# RA register map
Vendor: Renesas; Series: All Chips; File version: x.xx
Registers are 32-bit, read-write, reset 0x0 unless marked. A register's access mark holds for its fields unless they carry their own. Offsets are from the block's base; [hi:lo] are bit positions; lines under a group give offsets from that group; {n}, {i} and the like mark numbered series; 'fields as' and 'values as' point back to an identical list.

## R_USB_FS0 — USB 2.0 Module
Base 0x40090000
Same registers: R_USB_HS0 0x40060000
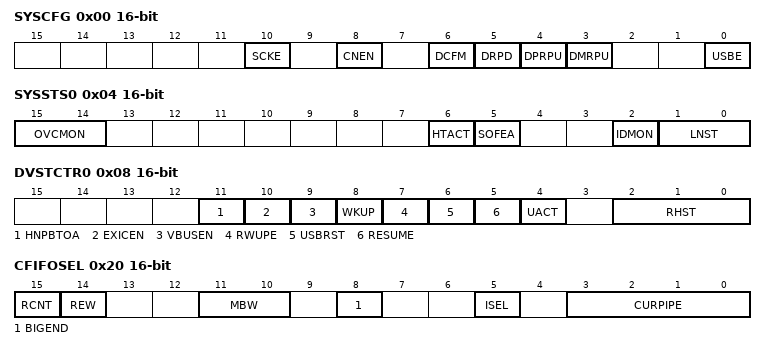
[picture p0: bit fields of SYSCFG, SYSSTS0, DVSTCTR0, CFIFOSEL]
0x00 SYSCFG 16-bit — System Configuration Control Register
  [10] SCKE — USB Clock Enable
    0=Clock supply to the USBFS stopped; 1=Clock supply to the USBFS enabled
  [8] CNEN — CNEN Single End Receiver Enable
    0=Single end receiver disabled; 1=Single end receiver enabled
  [6] DCFM — Controller Function Select
    0=Device controller selected; 1=Host controller selected
  [5] DRPD — D+/D- Line Resistor Control
    0=Line pull-down disabled; 1=Line pull-down enabled
  [4] DPRPU — D+ Line Resistor Control
    0=Line pull-down disabled; 1=Line pull-down enabled
  [3] DMRPU — D- Line Resistor Control
    0=Line pull-up disabled; 1=Line pull-up enabled
  [0] USBE — USB Operation Enable
    0=Disabled; 1=Enabled
0x02 BUSWAIT 16-bit reset 0xF — CPU Bus Wait Register
  [3:0] BWAIT — CPU Bus Access Wait Specification BWAIT waits (BWAIT+2 access cycles)
    other=BWAIT (BWAIT wait(s) ( BWAIT + 2 access cycles ))
0x04 SYSSTS0 16-bit ro reset not defined — System Configuration Status Register 0
  [15:14] OVCMON — External USB0_OVRCURA/ USB0_OVRCURB Input Pin MonitorThe OCVMON[1] bit indicates the status of the USBHS_OVRCURA pin. The OCVMON[0] bit indicates the status of the USBHS_OVRCURB pin.
  [6] HTACT — USB Host Sequencer Status Monitor
    0=Host sequencer completely stopped; 1=Host sequencer not completely stopped
  [5] SOFEA — SOF Active Monitor While Host Controller Function is Selected.
    0=SOF output is stopped; 1=SOF output is operating
  [2] IDMON — External ID0 Input Pin Monitor
    0=USB0_ID pin is low; 1=USB0_ID pin is high
  [1:0] LNST — USB Data Line Status Monitor
    0=SE0; 1=K-State (FS) / J-State(LS); 2=J-State(FS) / K-State(LS); 3=SE1
0x06 PLLSTA 16-bit ro — PLL Status Register
  [0] PLLLOCK — PLL Lock Flag
    0=PLL is not locked; 1=PLL is locked
0x08 DVSTCTR0 16-bit — Device State Control Register 0
  [11] HNPBTOA — Host Negotiation Protocol (HNP) Control This bit is used when switching from device B to device A while in OTG mode. If the HNPBTOA bit is 1, the internal function control keeps the suspended state until the HNP processing ends even though SYSCFG.DPRPU = 0 or SYSCFG.DCFM = 1 is set.
    0=Normal Operation; 1=Switching from device B to device A is enabled
  [10] EXICEN — USB_EXICEN Output Pin Control
    0=External USB_EXICEN pin outputs low; 1=External USB_EXICEN pin outputs high
  [9] VBUSEN — USB_VBUSEN Output Pin Control
    0=External USB_VBUSEN pin outputs low; 1=External USB_VBUSEN pin outputs high
  [8] WKUP — Wakeup Output
    0=Remote wakeup signal is not output; 1=Remote wakeup signal is output
  [7] RWUPE — Wakeup Detection Enable
    0=Downstream port wakeup is disabled; 1=Downstream port wakeup is enabled
  [6] USBRST — USB Bus Reset Output
    0=USB bus reset signal is not output; 1=USB bus reset signal is output
  [5] RESUME — Resume Output
    0=Resume signal is not output; 1=Resume signal is output
  [4] UACT — USB Bus Enable
    0=Downstream port is disabled (SOF transmission is disabled); 1=Downstream port is enabled (SOF transmission is enabled)
  [2:0] RHST ro — USB Bus Reset Status
    0=Communication speed not determined; 1=Low-speed connection(When the host controller is selected) /USB bus reset in progress( When the function controller is selected); 2=Full-speed connection(When the host controller is selected) /USB bus reset in progress or full-speed connection(When the function controller is selected); 3=Setting prohibited; other=others (USB bus reset in progress(When the host controller function is selected))
0x0C TESTMODE 16-bit — USB Test Mode Register
  [3:0] UTST — Test Mode
    0=Normal operation; 1=Test_J TestMode(When the Function Controller Function is Selected); 2=Test_K TestMode(When the Function Controller Function is Selected); 3=Test_SE0_NAK TestMode(When the Function Controller Function is Selected); 4=Test_Packet TestMode(When the Function Controller Function is Selected); 5=Reserved TestMode(When the Function Controller Function is Selected); 6=Reserved TestMode(When the Function Controller Function is Selected); 7=Reserved TestMode(When the Function Controller Function is Selected); 9=Test_J TestMode(When the Host Controller Function is Selected); 10=Test_K TestMode(When the Host Controller Function is Selected); 11=Test_SE0_NAK TestMode(When the Host Controller Function is Selected); 12=Test_Packet TestMode(When the Host Controller Function is Selected); 13=Test_Force_EnableTestMode(When the Host Controller Function is Selected); 14=Reserved TestMode(When the Host Controller Function is Selected); 15=Reserved TestMode(When the Host Controller Function is Selected)
0x14 CFIFOL 16-bit — CFIFO Port Register L
0x14 CFIFOLL 8-bit (alternate view of CFIFOL) — CFIFO Port Register LL
0x14 CFIFO (alternate view of CFIFOL) — CFIFO Port Register
0x16 CFIFOH 16-bit (alternate view of CFIFO) — CFIFO Port Register H
0x17 CFIFOHH 8-bit (alternate view of CFIFOH) — CFIFO Port Register HH
0x18 D0FIFOL 16-bit — D0FIFO Port Register L
0x18 D0FIFOLL 8-bit (alternate view of D0FIFOL) — D0FIFO Port Register LL
0x18 D0FIFO (alternate view of D0FIFOL) — D0FIFO Port Register
0x1A D0FIFOH 16-bit (alternate view of D0FIFO) — D0FIFO Port Register H
0x1B D0FIFOHH 8-bit (alternate view of D0FIFOH) — D0FIFO Port Register HH
0x1C D1FIFOL 16-bit — D1FIFO Port Register L
0x1C D1FIFOLL 8-bit (alternate view of D1FIFOL) — D1FIFO Port Register LL
0x1C D1FIFO (alternate view of D1FIFOL) — D1FIFO Port Register
0x1E D1FIFOH 16-bit (alternate view of D1FIFO) — D1FIFO Port Register H
0x1F D1FIFOHH 8-bit (alternate view of D1FIFOH) — D1FIFO Port Register HH
0x20 CFIFOSEL 16-bit — CFIFO Port Select Register
  [15] RCNT — Read Count Mode
    0=The DTLN[8:0] bits (CFIFOCRT.DTLN[8:0], D0FIFOCRT.DTLN[8:0], D1FIFOCRT.DTLN[8:0]) are cleared when all of the receive data has been read from the CFIFO.(In double buffer mode, the DTLN[8:0] bit value is cleared when all the data has been read from only a single plane.); 1=The DTLN[8:0] bits are decremented each time the receive data is read from the CFIFO
  [14] REW — Buffer Pointer Rewind
    0=The buffer pointer is not rewound; 1=The buffer pointer is rewound
  [11:10] MBW — CFIFO Port Access Bit Width
    0=8-bit width; 1=16-bit width; 2=32-bit width
  [8] BIGEND — CFIFO Port Endian Control
    0=Little endian; 1=Big endian
  [5] ISEL — CFIFO Port Access Direction When DCP is Selected
    0=Reading from the buffer memory is selected; 1=Writing to the buffer memory is selected
  [3:0] CURPIPE — CFIFO Port Access Pipe Specification
    0=DCP (Default control pipe); {v}=Pipe {v} (v=1..9); other=others (Setting prohibited)
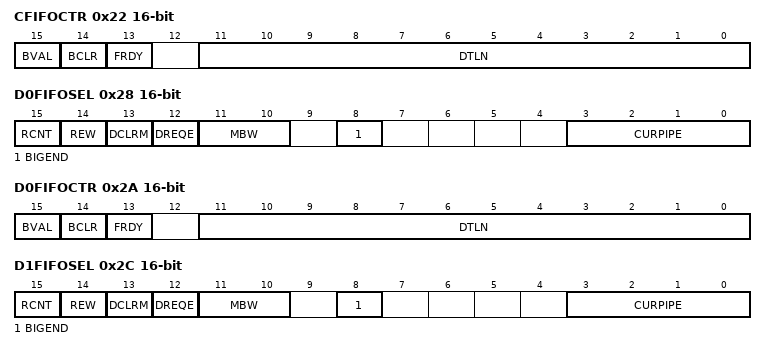
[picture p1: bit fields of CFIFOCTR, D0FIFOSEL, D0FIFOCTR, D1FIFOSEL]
0x22 CFIFOCTR 16-bit — CFIFO Port Control Register
  [15] BVAL — Buffer Memory Valid Flag
    0=Invalid; 1=Writing ended
  [14] BCLR — CPU Buffer ClearNote: Only 0 can be read.
    0=Does not operate; 1=FIFO buffer cleared on the CPU side
  [13] FRDY ro — FIFO Port Ready
    0=FIFO port access is disabled; 1=FIFO port access is enabled
  [11:0] DTLN ro — Receive Data LengthIndicates the length of the receive data.
0x28 D0FIFOSEL 16-bit — D0FIFO Port Select Register
  [15] RCNT — Read Count Mode
    0=The DTLN[8:0] bits (CFIFOCRT.DTLN[8:0], D0FIFOCRT.DTLN[8:0], D1FIFOCRT.DTLN[8:0]) are cleared when all of the receive data has been read from the DnFIFO.(In double buffer mode, the DTLN bit Value is cleared when all the data has been read from only a single plane.); 1=The DTLN[8:0] bits are decremented each time the receive data is read from the DnFIFO. (n = 0, 1)
  [14] REW — Buffer Pointer RewindNote: Only 0 can be read.
    values as CFIFOSEL.REW
  [13] DCLRM — Auto Buffer Memory Clear Mode Accessed after Specified Pipe Data is Read
    0=Auto buffer clear mode is disabled; 1=Auto buffer clear mode is enabled
  [12] DREQE — DMA/DTC Transfer Request Enable
    0=DMA/DTC transfer request is disabled; 1=DMA/DTC transfer request is enabled
  [11:10] MBW — FIFO Port Access Bit Width
    0=8-bit width; 1=16-bit width; 2=32-bit width
  [8] BIGEND — FIFO Port Endian Control
    0=Little endian; 1=Big endian
  [3:0] CURPIPE — FIFO Port Access Pipe Specification
    values as CFIFOSEL.CURPIPE
0x2A D0FIFOCTR 16-bit — D0FIFO Port Control Register
  fields as CFIFOCTR
0x2C D1FIFOSEL 16-bit — D1FIFO Port Select Register
  [15] RCNT — Read Count Mode
    values as D0FIFOSEL.RCNT
  [14] REW — Buffer Pointer Rewind
    values as CFIFOSEL.REW
  [13] DCLRM — Auto Buffer Memory Clear Mode Accessed after Specified Pipe Data is Read
    values as D0FIFOSEL.DCLRM
  [12] DREQE — DMA/DTC Transfer Request Enable
    values as D0FIFOSEL.DREQE
  [11:10] MBW — FIFO Port Access Bit Width
    0=8-bit width; 1=16-bit width; 2=32-bit width
  [8] BIGEND — FIFO Port Endian Control
    0=Little endian; 1=Big endian
  [3:0] CURPIPE — FIFO Port Access Pipe Specification
    values as CFIFOSEL.CURPIPE
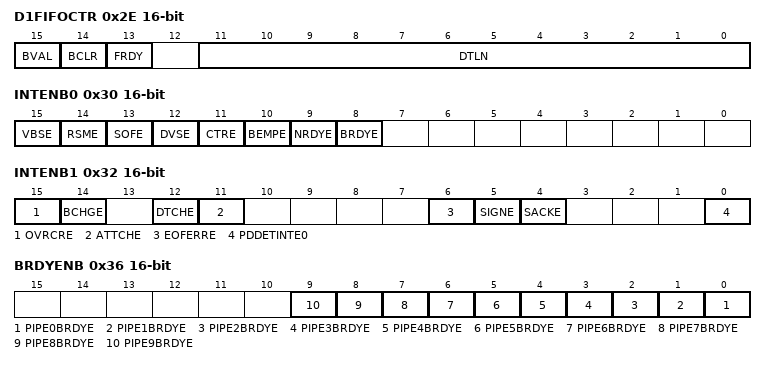
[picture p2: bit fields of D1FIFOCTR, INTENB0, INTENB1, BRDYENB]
0x2E D1FIFOCTR 16-bit — D1FIFO Port Control Register
  fields as CFIFOCTR
0x30 INTENB0 16-bit — Interrupt Enable Register 0
  [all] fields
    0=Interrupt output disabled; 1=Interrupt output enabled
  [15] VBSE — VBUS Interrupt Enable
  [14] RSME — Resume Interrupt Enable
  [13] SOFE — Frame Number Update Interrupt Enable
  [12] DVSE — Device State Transition Interrupt Enable
  [11] CTRE — Control Transfer Stage Transition Interrupt Enable
  [10] BEMPE — Buffer Empty Interrupt Enable
  [9] NRDYE — Buffer Not Ready Response Interrupt Enable
  [8] BRDYE — Buffer Ready Interrupt Enable
0x32 INTENB1 16-bit — Interrupt Enable Register 1
  [all] fields
    0=Interrupt output disabled; 1=Interrupt output enabled
  [15] OVRCRE — Overcurrent Input Change Interrupt Enable
  [14] BCHGE — USB Bus Change Interrupt Enable
  [12] DTCHE — Disconnection Detection Interrupt Enable
  [11] ATTCHE — Connection Detection Interrupt Enable
  [6] EOFERRE — EOF Error Detection Interrupt Enable
  [5] SIGNE — Setup Transaction Error Interrupt Enable
  [4] SACKE — Setup Transaction Normal Response Interrupt Enable
  [0] PDDETINTE0 — PDDETINT0 Detection Interrupt Enable
0x36 BRDYENB 16-bit — BRDY Interrupt Enable Register
  [n] PIPE{n}BRDYE (n=0..9) — BRDY Interrupt Enable for PIPE
    0=Interrupt output disabled; 1=Interrupt output enabled
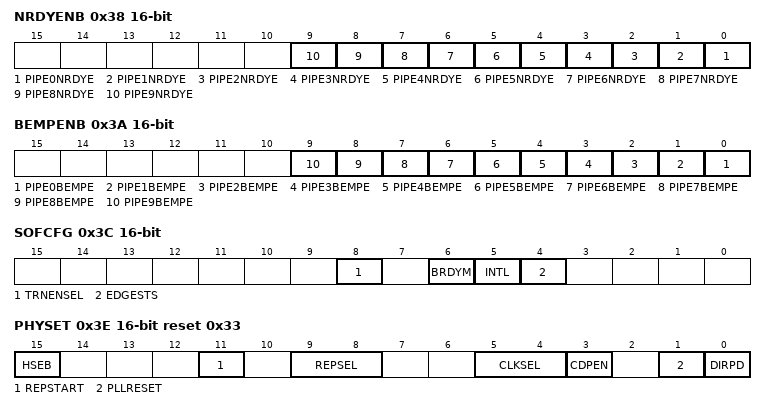
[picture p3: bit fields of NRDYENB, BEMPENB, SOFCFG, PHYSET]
0x38 NRDYENB 16-bit — NRDY Interrupt Enable Register
  [n] PIPE{n}NRDYE (n=0..9) — NRDY Interrupt Enable for PIPE
    0=Interrupt output disabled; 1=Interrupt output enabled
0x3A BEMPENB 16-bit — BEMP Interrupt Enable Register
  [n] PIPE{n}BEMPE (n=0..9) — BEMP Interrupt Enable for PIPE
    0=Interrupt output disabled; 1=Interrupt output enabled
0x3C SOFCFG 16-bit — SOF Output Configuration Register
  [8] TRNENSEL — Transaction-Enabled Time Select
    0=Not low-speed communication; 1=Low-speed communication
  [6] BRDYM — BRDY Interrupt Status Clear Timing
    0=BRDY flag cleared by software; 1=BRDY flag cleared by the USBFS through a data read from the FIFO buffer or data write to the FIFO buffer
  [5] INTL — Interrupt Output Sense Select
    0=Edge sense; 1=Level sense
  [4] EDGESTS ro — Edge Interrupt Output Status Monitor
    0=before stopping the clock supply to the USB module; 1=the edge interrupt output signal is in the middle of the edge processing
0x3E PHYSET 16-bit reset 0x33 (reset mask 0xB3B) — PHY Setting Register
  [15] HSEB — CL-Only Mode
    0=CL-only mode is not activated; 1=CL-only mode is activated
  [11] REPSTART — Forcibly Start Terminating Resistance Adjustment
    0=Terminating resistance adjustment is forcibly started; 1=Terminating resistance adjustment is not forcibly started
  [9:8] REPSEL — Terminating Resistance Adjustment Cycle
    0=No cycle is set; 1=Adjust terminating resistance at 16-second intervals; 2=Adjust terminating resistance at 64-second intervals; 3=Adjust terminating resistance at 128-second intervals
  [5:4] CLKSEL — Input System Clock Frequency
    0=Setting Prohibited; 1=12 MHz; 2=20 MHz; 3=24 MHz
  [3] CDPEN — Charging Downstream Port Enable
    0=Disable charging downstream port; 1=Enable charging downstream port
  [1] PLLRESET — PLL Reset Control
    0=Disable PLL reset control for UTMI_PHY; 1=Enable PLL reset control for UTMI_PHY
  [0] DIRPD — Power-Down Control
    0=Does not enter low-power consumption mode; 1=Enter low-power consumption mode
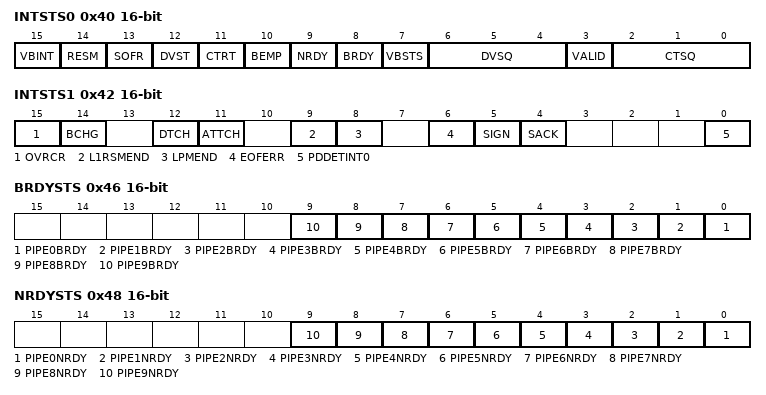
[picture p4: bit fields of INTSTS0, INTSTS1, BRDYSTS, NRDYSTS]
0x40 INTSTS0 16-bit (reset mask 0xFF7F) — Interrupt Status Register 0
  [15] VBINT write-0-clears read-modifies — VBUS Interrupt Status
    0=VBUS interrupts are not generated; 1=VBUS interrupts are generated
  [14] RESM write-0-clears read-modifies — Resume Interrupt Status
    0=Resume interrupts are not generated; 1=Resume interrupts are generated
  [13] SOFR write-0-clears read-modifies — Frame Number Refresh Interrupt Status
    0=SOF interrupts are not generated; 1=SOF interrupts are generated
  [12] DVST write-0-clears read-modifies — Device State Transition Interrupt Status
    0=Device state transition interrupts are not generated; 1=Device state transition interrupts are generated
  [11] CTRT write-0-clears read-modifies — Control Transfer Stage Transition Interrupt Status
    0=Control transfer stage transition interrupts are not generated; 1=Control transfer stage transition interrupts are generated
  [10] BEMP ro — Buffer Empty Interrupt Status
    0=BEMP interrupts are not generated; 1=BEMP interrupts are generated
  [9] NRDY ro — Buffer Not Ready Interrupt Status
    0=NRDY interrupts are not generated; 1=NRDY interrupts are generated
  [8] BRDY ro — Buffer Ready Interrupt Status
    0=BRDY interrupts are not generated; 1=BRDY interrupts are generated
  [7] VBSTS ro — VBUS Input Status
    0=USB_VBUS pin is low; 1=USB_VBUS pin is high
  [6:4] DVSQ ro — Device State
    0=Powered state; 1=Default state; 2=Address state; 3=Configured state; other=others (Suspended state)
  [3] VALID — USB Request Reception
    0=Setup packet is not received; 1=Setup packet is received
  [2:0] CTSQ ro — Control Transfer Stage
    0=Idle or setup stage; 1=Control read data stage; 2=Control read status stage; 3=Control write data stage; 4=Control write status stage; 5=Control write (no data) status stage; 6=Control transfer sequence error; other=others (Setting prohibited)
0x42 INTSTS1 16-bit — Interrupt Status Register 1
  [15] OVRCR write-0-clears read-modifies — Overcurrent Input Change Interrupt Status
    0=OVRCR interrupts are not generated; 1=OVRCR interrupts are generated
  [14] BCHG write-0-clears read-modifies — USB Bus Change Interrupt Status
    0=BCHG interrupts are not generated; 1=BCHG interrupts are generated
  [12] DTCH write-0-clears read-modifies — USB Disconnection Detection Interrupt Status
    0=DTCH interrupts are not generated; 1=DTCH interrupts are generated
  [11] ATTCH write-0-clears read-modifies — ATTCH Interrupt Status
    0=ATTCH interrupts are not generated; 1=ATTCH interrupts are generated
  [9] L1RSMEND write-0-clears read-modifies — L1 Resume End Interrupt Status
    0=L1RSMEND interrupts are not generated; 1=L1RSMEND interrupts are generated
  [8] LPMEND write-0-clears read-modifies — LPM Transaction End Interrupt Status
    0=LPMEND interrupts are not generated; 1=LPMEND interrupts are generated
  [6] EOFERR write-0-clears read-modifies — EOF Error Detection Interrupt Status
    0=EOFERR interrupts are not generated; 1=EOFERR interrupts are generated
  [5] SIGN write-0-clears read-modifies — Setup Transaction Error Interrupt Status
    0=SIGN interrupts are not generated; 1=SIGN interrupts are generated
  [4] SACK write-0-clears read-modifies — Setup Transaction Normal Response Interrupt Status
    0=SACK interrupts are not generated; 1=SACK interrupts are generated
  [0] PDDETINT0 write-0-clears read-modifies — PDDET0 Detection Interrupt Status
    0=PDDET0 detection interrupts are not generated; 1=PDDET0 detection interrupts are generated
0x46 BRDYSTS 16-bit — BRDY Interrupt Status Register
  [n] PIPE{n}BRDY (n=0..9) write-0-clears read-modifies — BRDY Interrupt Status for PIPE
    0=Interrupts are not generated; 1=Interrupts are generated
0x48 NRDYSTS 16-bit — NRDY Interrupt Status Register
  [n] PIPE{n}NRDY (n=0..9) write-0-clears read-modifies — NRDY Interrupt Status for PIPE
    0=Interrupts are not generated; 1=Interrupts are generated
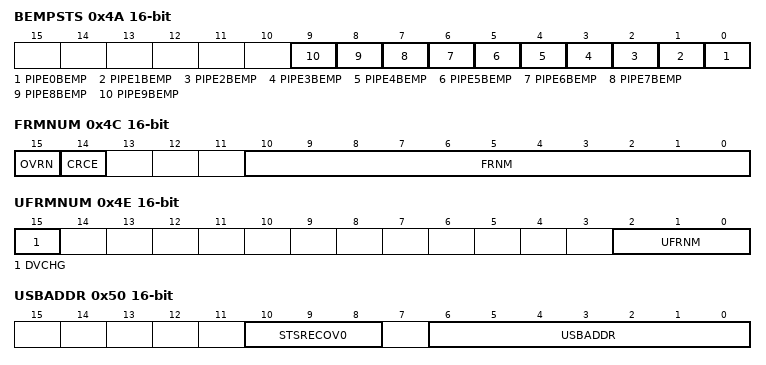
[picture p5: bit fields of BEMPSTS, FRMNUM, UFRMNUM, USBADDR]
0x4A BEMPSTS 16-bit — BEMP Interrupt Status Register
  [n] PIPE{n}BEMP (n=0..9) write-0-clears read-modifies — BEMP Interrupt Status for PIPE
    0=Interrupts are not generated; 1=Interrupts are generated
0x4C FRMNUM 16-bit — Frame Number Register
  [15] OVRN — Overrun/Underrun Detection Status
    0=No error; 1=An error occurred
  [14] CRCE — Receive Data Error
    0=No error; 1=An error occurred
  [10:0] FRNM ro — Frame NumberLatest frame number
0x4E UFRMNUM 16-bit — uFrame Number Register
  [15] DVCHG — Device State Change
    0=Disables the writing to the USBADDR.STSRECOV0[2:0] bits and USBADDR.USBADDR[6:0]; 1=Enables the writing to the USBADDR.STSRECOV0[2:0] bits and USBADDR.USBADDR[6:0]
  [2:0] UFRNM ro — MicroframeIndicate the microframe number.
0x50 USBADDR 16-bit — USB Address Register
  [10:8] STSRECOV0 — Status Recovery
    1=Return to the full-speed state(bits DVSTCTR0.RHST[2:0] = 010b), bits INTSTS0.DVSQ[2:0] = 001b (Default state)(function controller selected); 2=Return to the full-speed state (bits DVSTCTR0.RHST[2:0] = 010b), bits INTSTS0.DVSQ[2:0] = 010b (Address state)(function controller selected)/ Return to the low-speed state (bitsDVSTCTR0.RHST[2:0] = 001b)(host controller is selected); 3=Return to the full-speed state (bits DVSTCTR0.RHST[2:0] = 010b), bits INTSTS0.DVSQ[2:0] = 011b (Configured state)(function controller selected); 4=Return to the full-speed state (bits DVSTCTR0.RHST[2:0] = 010b)(host controller selected); 5=Return to the high-speed state (bits DVSTCTR0.RHST[2:0] = 011b), bits INTSTS0.DVSQ[2:0] = 001b (Default state)(function controller selected); 6=Return to the high-speed state (bits DVSTCTR0.RHST[2:0] = 011b), bits INTSTS0.DVSQ[2:0] = 010b (Address state)(function controller selected)/ Return to the high-speed state (bits DVSTCTR0.RHST[2:0] = 011b)(host controller selected); 7=Return to the high-speed state (bits DVSTCTR0.RHST[2:0] = 011b), bits INTSTS0.DVSQ[2:0] = 011b (Configured state)(function controller selected); other=others (Setting prohibited.)
  [6:0] USBADDR ro — USB Address In device controller mode, these flags indicate the USB address assigned by the host when the USBHS processed the SET_ADDRESS request successfully.
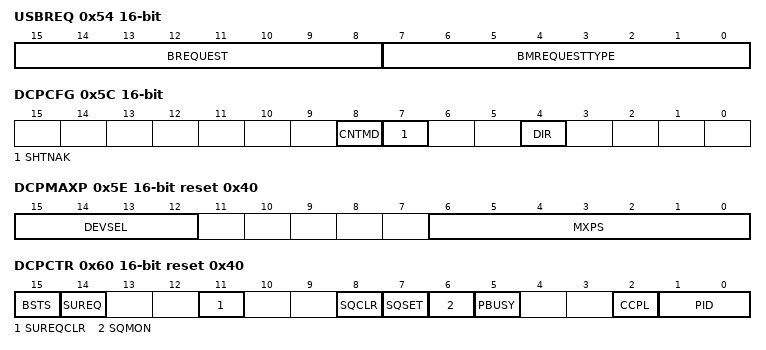
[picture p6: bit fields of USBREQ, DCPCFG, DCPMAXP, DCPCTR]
0x54 USBREQ 16-bit — USB Request Type Register
  [15:8] BREQUEST — RequestThese bits store the USB request bRequest value.
  [7:0] BMREQUESTTYPE — Request TypeThese bits store the USB request bmRequestType value.
0x56 USBVAL 16-bit — USB Request Value Register
  [15:0] WVALUE — ValueThese bits store the USB request Value value.
0x58 USBINDX 16-bit — USB Request Index Register
  [15:0] WINDEX — IndexThese bits store the USB request wIndex value.
0x5A USBLENG 16-bit — USB Request Length Register
  [15:0] WLENGTH — LengthThese bits store the USB request wLength value.
0x5C DCPCFG 16-bit — DCP Configuration Register
  [8] CNTMD — Continuous Transfer Mode
    0=Non-continuous transfer mode; 1=Continuous transfer mode
  [7] SHTNAK — Pipe Disabled at End of Transfer
    0=Pipe continued at the end of transfer; 1=Pipe disabled at the end of transfer
  [4] DIR — Transfer Direction
    0=Data receiving direction; 1=Data transmitting direction
0x5E DCPMAXP 16-bit reset 0x40 — DCP Maximum Packet Size Register
  [15:12] DEVSEL — Device Select
    0=Address 0000; 1=Address 0001; 2=Address 0010; 3=Address 0011; 4=Address 0100; 5=Address 0101; other=others (Settings prohibited.)
  [6:0] MXPS — Maximum Packet SizeThese bits set the maximum amount of data (maximum packet size) in payloads for the DCP.
    8=8 bytes; 16=16 bytes; 24=24 bytes; 32=32 bytes; 40=40 bytes; 48=48 bytes; 56=56 bytes; 64=64 bytes; 72=72 bytes; 80=80 bytes; 88=88 bytes; 96=96 bytes; 104=104 bytes; 112=112 bytes; 120=120 bytes; other=others (Setting prohibited)
0x60 DCPCTR 16-bit reset 0x40 — DCP Control Register
  [15] BSTS ro — Buffer Status
    0=Buffer access is disabled; 1=Buffer access is enabled
  [14] SUREQ — Setup Token Transmission
    0=Invalid; 1=Transmits the setup packet
  [11] SUREQCLR — SUREQ Bit Clear
    0=Invalid; 1=Clears the SUREQ bit to 0
  [8] SQCLR — Sequence Toggle Bit Clear
    0=Invalid; 1=Specifies DATA0
  [7] SQSET — Sequence Toggle Bit Set
    0=Invalid; 1=Specifies DATA1
  [6] SQMON ro — Sequence Toggle Bit Monitor
    0=DATA0; 1=DATA1
  [5] PBUSY ro — Pipe Busy
    0=DCP is not used for the transaction; 1=DCP is used for the transaction
  [2] CCPL — Control Transfer End Enable
    0=Invalid; 1=Completion of control transfer is enabled
  [1:0] PID — Response PID
    0=NAK response; 1=BUF response (depending on the buffer state); 2=STALL response; 3=STALL response
0x64 PIPESEL 16-bit — Pipe Window Select Register
  [3:0] PIPESEL — Pipe Window Select
    0=No pipe selected; {v}=PIPE{v} (v=1..9); other=others (Settings prohibited.)
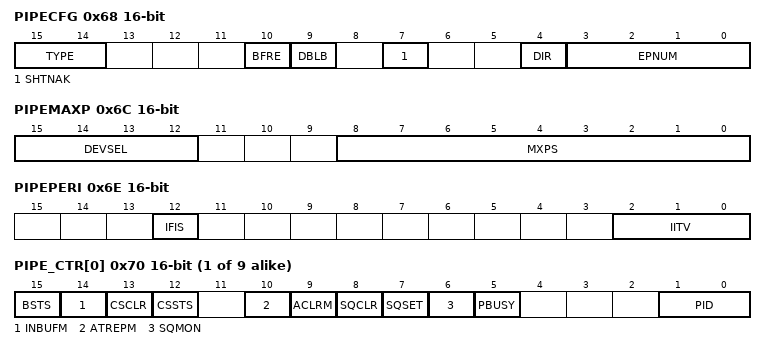
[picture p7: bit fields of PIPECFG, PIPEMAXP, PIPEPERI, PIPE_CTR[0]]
0x68 PIPECFG 16-bit — Pipe Configuration Register
  [15:14] TYPE — Transfer Type
    0=Pipe not used; 1=Bulk transfer(PIPE1 and PIPE5) /Setting prohibited(PIPE6 to PIPE9); 2=Setting prohibited(PIPE1 and PIPE5) /Interrupt transfer(PIPE6 to PIPE9); 3=Isochronous transfer(PIPE1 and PIPE2) /Setting prohibited(PIPE3 to PIPE9)
  [10] BFRE — BRDY Interrupt Operation Specification
    0=BRDY interrupt upon transmitting or receiving data; 1=BRDY interrupt upon completion of reading data
  [9] DBLB — Double Buffer Mode
    0=Single buffer; 1=Double buffer
  [7] SHTNAK — Pipe Disabled at End of Transfer
    0=Continue pipe operation after transfer ends; 1=Disable pipe operation after transfer ends
  [4] DIR — Transfer Direction
    0=Receiving direction; 1=Transmitting direction
  [3:0] EPNUM — Endpoint NumberThese bits specify the endpoint number for the selected pipe.Setting 0000b means unused pipe.
0x6C PIPEMAXP 16-bit (reset mask 0xFFBF) — Pipe Maximum Packet Size Register
  [15:12] DEVSEL — Device Select
    values as DCPMAXP.DEVSEL
  [8:0] MXPS — Maximum Packet SizePIPE1 and PIPE2: 1 byte (001h) to 256 bytes (100h)PIPE3 to PIPE5: 8 bytes (008h), 16 bytes (010h), 32 bytes (020h), 64 bytes (040h) (Bits [8:7] and [2:0] are not provided.)PIPE6 to PIPE9: 1 byte (001h) to 64 bytes (040h) (Bits [8:7] are not provided.)
0x6E PIPEPERI 16-bit — Pipe Cycle Control Register
  [12] IFIS — Isochronous IN Buffer Flush
    0=The buffer is not flushed; 1=The buffer is flushed
  [2:0] IITV — Interval Error Detection IntervalSpecifies the interval error detection timing for the selected pipe in terms of frames, which is expressed as nth power of 2.
{0x70+2i} PIPE_CTR[{i}] (i=0..8) 16-bit — Pipe {i} Control Register
  [15] BSTS ro — Buffer Status
    0=Buffer access by the CPU is disabled; 1=Buffer access by the CPU is enabled
  [14] INBUFM ro — Transmit Buffer Monitor
    0=No data to be transmitted is in the FIFO buffer; 1=Data to be transmitted is in the FIFO buffer
  [13] CSCLR — CSPLIT Status ClearSet this bit to 1 when clearing the CSSTS bit of the relevant pipe
    0=Writing is disabled; 1=The CSSTS bit is cleared
  [12] CSSTS ro — CSSTS StatusThis bit indicates the CSPLIT status of Split Transaction of the relevant pipe
    0=SSplit Transaction processing is in progress or transfer without Split Transaction is in progress; 1=CSplit Transaction processing is in progress
  [10] ATREPM — Auto Response Mode
    0=Auto response disabled; 1=Auto response enabled
  [9] ACLRM — Auto Buffer Clear Mode
    0=Disabled; 1=Enabled (all buffers are initialized)
  [8] SQCLR — Sequence Toggle Bit Clear
    0=Write disabled; 1=Specifies DATA0
  [7] SQSET — Sequence Toggle Bit Set
    0=Write disabled; 1=Specifies DATA1
  [6] SQMON ro — Sequence Toggle Bit Confirmation
    0=DATA0; 1=DATA1
  [5] PBUSY ro — Pipe Busy
    0=Pipe n not in use for the transaction; 1=Pipe n in use for the transaction
  [1:0] PID — Response PID
    values as DCPCTR.PID
{0x90+4i} PIPE_TR[{i}] (i=0..4) group — Pipe Transaction Counter Registers
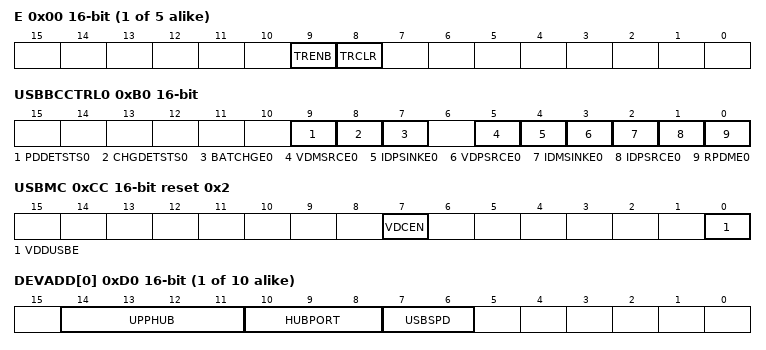
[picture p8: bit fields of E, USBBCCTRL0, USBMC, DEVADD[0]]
  0x00 E 16-bit — Pipe Transaction Counter Enable Register
    [9] TRENB — Transaction Counter Enable
      0=Transaction counter is disabled; 1=Transaction counter is enabled
    [8] TRCLR — Transaction Counter Clear
      0=Invalid; 1=The current counter value is cleared
  0x02 N 16-bit — Pipe Transaction Counter Register
    [15:0] TRNCNT — Transaction Counter
0xB0 USBBCCTRL0 16-bit — BC Control Register 0
  [9] PDDETSTS0 ro — D+ Pin 0.6 V Input Detection Status
    0=Not detected; 1=Detected
  [8] CHGDETSTS0 ro — D- Pin 0.6 V Input Detection Status
    0=Not detected; 1=Detected
  [7] BATCHGE0 — BC (Battery Charger) Function Ch0 General Enable Control
    0=Disabled; 1=Enabled
  [5] VDMSRCE0 — D- Pin VDMSRC (0.6 V) Output Control
    0=Stop; 1=0.6V output
  [4] IDPSINKE0 — D+ Pin 0.6 V Input Detection (Comparator and Sink) Control
    0=Detection off; 1=Detection on ( Comparator and sink current on )
  [3] VDPSRCE0 — D+ Pin VDPSRC (0.6 V) Output Control
    0=Stop; 1=0.6V output
  [2] IDMSINKE0 — D- Pin 0.6 V Input Detection (Comparator and Sink) Control
    values as IDPSINKE0
  [1] IDPSRCE0 — D+ Pin IDPSRC Output Control
    0=Stop; 1=10uA output
  [0] RPDME0 — D- Pin Pull-Down Control
    0=Pull-down off; 1=Pull-down on
0xC4 UCKSEL 16-bit — USB Clock Selection Register
  [0] UCKSELC — USB Clock Selection
    0=High-speed on-chip oscillator clock (HOCO) is not selected as USB clock; 1=High-speed on-chip oscillator clock (HOCO) is selected as USB clock
0xCC USBMC 16-bit reset 0x2 — USB Module Control Register
  [7] VDCEN — USB Regulator On/Off Control
    0=USB regulator off; 1=USB regulator on
  [0] VDDUSBE — USB Reference Power Supply Circuit On/Off Control
    0=USB reference power supply circuit off; 1=USB reference power supply circuit on
{0xD0+2i} DEVADD[{i}] (i=0..9) 16-bit — Device Address Configuration Register
  [14:11] UPPHUB range 0x0000..0x1010 — Communication Target Connecting Hub Register
    0=Directly connected to the port of the USBHS; other=UPPHUB (USB address of the hub)
  [10:8] HUBPORT — Communication Target Connecting Hub Port
    0=Directly connected to the port of the USBHS; other=others (Port number of the hub)
  [7:6] USBSPD — Transfer Speed of Communication Target Device
    0=DEVADDn is not used; 1=Low speed; 2=Full speed; 3=Setting prohibited
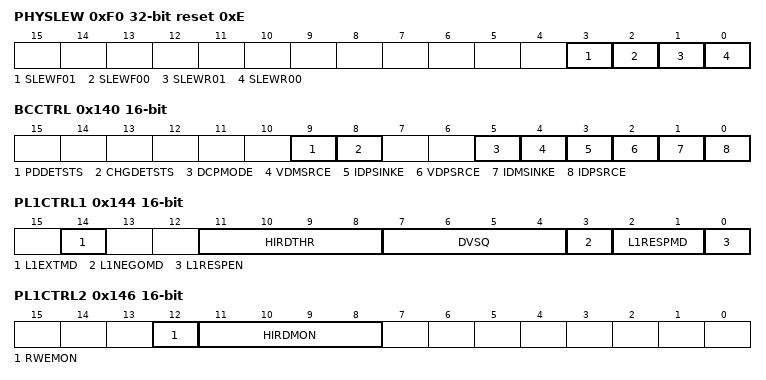
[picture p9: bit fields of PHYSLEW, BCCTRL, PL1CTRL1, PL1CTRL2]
0xF0 PHYSLEW reset 0xE — PHY Cross Point Adjustment Register
  [all] fields
    1=Host or device controller mode
  [3] SLEWF01 — Receiver Cross Point Adjustment 01
  [2] SLEWF00 — Receiver Cross Point Adjustment 00
  [1] SLEWR01 — Receiver Cross Point Adjustment 01
  [0] SLEWR00 — Receiver Cross Point Adjustment 00
0x100 LPCTRL 16-bit — Low Power Control Register
  [7] HWUPM — Resume Return Mode Setting
    0=Hardware does not recover while CPU clock inactive; 1=Hardware recovers while CPU clock inactive
0x102 LPSTS 16-bit — Low Power Status Register
  [14] SUSPENDM — UTMI SuspendM Control
    0=UTMI suspension mode; 1=UTMI normal mode
0x140 BCCTRL 16-bit — Battery Charging Control Register
  [9] PDDETSTS ro — PDDET Status
    0=The PDDET pin is at low level; 1=The PDDET pin is at high level
  [8] CHGDETSTS ro — CHGDET Status
    0=The CHGDET pin is at low level; 1=The CHGDET pin is at high level
  [5] DCPMODE — DCP Mode Control
    0=The RDCP_DAT resistor is disabled; 1=The RDCP_DAT resistor is enabled
  [4] VDMSRCE — VDMSRC Control
    0=The VDM_SRC circuit is disabled. (Initial value); 1=The VDM_SRC circuit is enabled
  [3] IDPSINKE — IDPSINK Control
    0=The IDP_SINK circuit is disabled. (Initial value); 1=The IDP_SINK circuit is enabled
  [2] VDPSRCE — VDPSRC Control
    0=The VDP_SRC circuit is disabled. (Initial value); 1=The VDP_SRC circuit is enabled
  [1] IDMSINKE — IDMSINK Control
    0=The IDM_SINK circuit is disabled. (Initial value); 1=The IDM_SINK circuit is enabled
  [0] IDPSRCE — IDPSRC Control
    0=The IDP_SRC circuit is disabled. (Initial value); 1=The IDP_SRC circuit is enabled
0x144 PL1CTRL1 16-bit — Function L1 Control Register 1
  [14] L1EXTMD — PHY Control Mode at L1 Return
    0=SUSPENDM is not set by hardware when Host K is received; 1=SUSPENDM is set by hardware when Host K is received
  [11:8] HIRDTHR — L1 Response Negotiation Threshold ValueHIRD threshold value used for L1NEGOMD.The format is the same as the HIRD field in HL1CTRL.
  [7:4] DVSQ ro — DVSQ Extension.DVSQ[3] is Mirror of DVSQ[2:0] in INTSTS0.Indicates the L1 state together with the device state bits DVSQ[2:0].
    0=Powered state; 1=Default state; 2=Address state; 3=Configured state; {v}=Suspended state (v=4..7); {v}=L1 state (v=8..11); other=others (setting prohibited)
  [3] L1NEGOMD — L1 Response Negotiation Control.NOTE: This bit is valid only when the L1RESPMD[1:0] value is 2'b11.
    0=When receive HIRD is larger than HIRDTHR[3:0], ACK response is returned. In other cases (including HIRD = HIRDTHR[3:0]), NYET response is returned.; 1=When receive HIRD is smaller than HIRDTHR[3:0], ACK response is returned. In other cases (including HIRD = HIRDTHR[3:0]), NYET response is returned.
  [2:1] L1RESPMD — L1 Response Mode
    0=NYET; 1=ACK; 2=STALL; 3=According to the L1NEGOMD bit
  [0] L1RESPEN — L1 Response Enable
    0=LPM is not supported; 1=LPM is supported
0x146 PL1CTRL2 16-bit — Function L1 Control Register 2
  [12] RWEMON — RWE Value Monitor
    0=The RWE bit value of the LPM token received last is reflected; 1=The RWE bit value of the LPM token received last is reflected
  [11:8] HIRDMON — HIRD Value Monitor
    0=The HIRD field value of the LPM token received last is reflected; 1=The HIRD field value of the LPM token received last is reflected
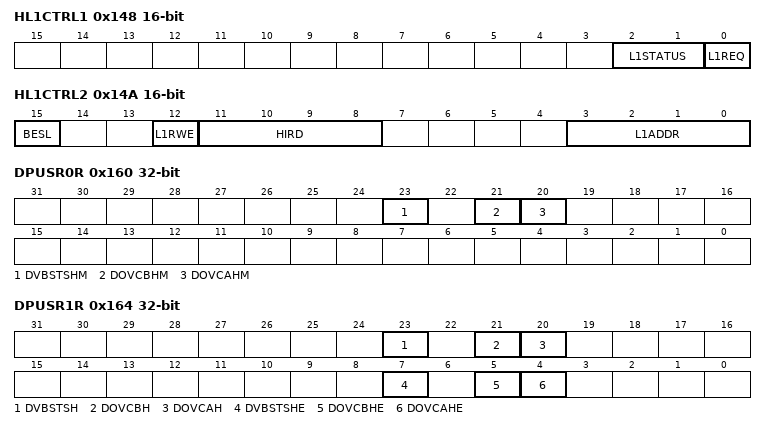
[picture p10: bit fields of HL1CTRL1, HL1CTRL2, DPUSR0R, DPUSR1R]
0x148 HL1CTRL1 16-bit — Host L1 Control Register 1
  [2:1] L1STATUS ro — L1 Request Completion Status
    0=ACK received; 1=NYET received; 2=STALL received; 3=Transaction error
  [0] L1REQ — L1 Transition Request
    0=This bit is cleared to 0 by hardware when the LPM transaction is completed; 1=Set this bit to 1 when requesting a transition to the L1 state
0x14A HL1CTRL2 16-bit — Host L1 Control Register 2
  [15] BESL — BESL & Alternate HIRDThis bit selects the K-State drive period at the time of L1 Resume.
  [12] L1RWE — LPM Token L1 RemoteWake EnableThese bits specify the value to be set in the RWE field of LPM token.
  [11:8] HIRD — LPM Token HIRD
    0=50 us(Setting prohibited(BESL = 0)) / 75 us(BESL = 1); 1=125 us(BESL = 0) / 100 us(BESL = 1); 2=200 us(BESL = 0) / 150 us(BESL = 1); 3=275 us(BESL = 0) / 250 us(BESL = 1); 4=350 us(BESL = 0) / 350 us(BESL = 1); 5=425 us(BESL = 0) / 450 us(BESL = 1); 6=500 us(BESL = 0) / 950 us(BESL = 1); 7=575 us(BESL = 0) / 1950 us(BESL = 1); 8=650 us(BESL = 0) / 2950 us(BESL = 1); 9=725 us(BESL = 0) / 3950 us(BESL = 1); 10=800 us(BESL = 0) / 4950 us(BESL = 1); 11=875 us(BESL = 0) / 5950 us(BESL = 1); 12=950 us(BESL = 0) / 6950 us(BESL = 1); 13=1025 us(Setting prohibited(BESL = 0)) / 7950 us(BESL = 1); 14=1100 us(Setting prohibited(BESL = 0)) / 8950 us(BESL = 1); 15=1175 us(Setting prohibited(BESL = 0)) / 9950 us(BESL = 1)
  [3:0] L1ADDR — LPM Token DeviceAddressThese bits specify the value to be set in the ADDR field of LPM token.
0x160 DPUSR0R ro (reset mask 0xFF4FFFFF) — Deep Standby USB Transceiver Control/Pin Monitor Register
  [23] DVBSTSHM — VBUS InputIndicates VBUS input signal on the HS side of USB port.
  [21] DOVCBHM — OVRCURB InputIndicates OVRCURB input signal on the HS side of USB port.
  [20] DOVCAHM — OVRCURA InputIndicates OVRCURA input signal on the HS side of USB port.
0x164 DPUSR1R — Deep Standby USB Suspend/Resume Interrupt Register
  [23] DVBSTSH ro — Indication of Return from VBUS Interrupt Source
    0=Indicates deep software standby mode; 1=Indicates return from deep software standby mode
  [21] DOVCBH ro — Indication of Return from OVRCURB Interrupt Source
    values as DVBSTSH
  [20] DOVCAH ro — Indication of Return from OVRCURA Interrupt Source
    values as DVBSTSH
  [7] DVBSTSHE — VBUS Interrupt Enable/Clear
    0=Disables return from deep software standby mode; 1=Enables return from deep software standby mode
  [5] DOVCBHE — OVRCURB Interrupt Enable Clear
    values as DVBSTSHE
  [4] DOVCAHE — OVRCURA Interrupt Enable Clear
    values as DVBSTSHE
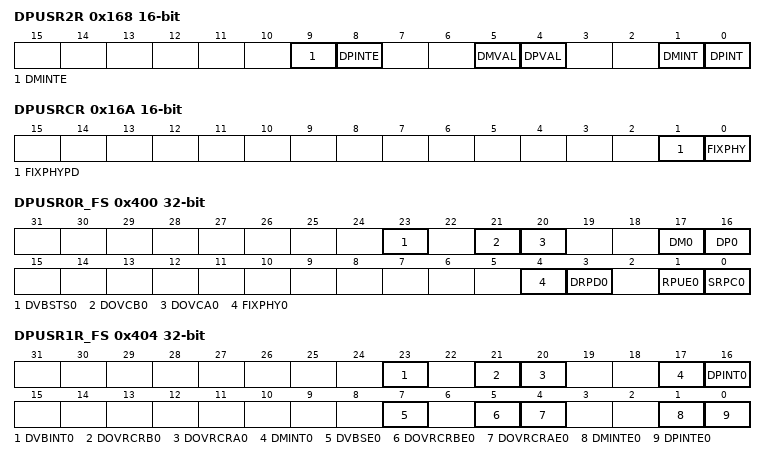
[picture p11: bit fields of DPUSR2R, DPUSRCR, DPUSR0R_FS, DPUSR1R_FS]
0x168 DPUSR2R 16-bit — Deep Standby USB Suspend/Resume Interrupt Register
  [9] DMINTE — DM Interrupt Enable Clear
    values as DPUSR1R.DVBSTSHE
  [8] DPINTE — DP Interrupt Enable Clear
    values as DPUSR1R.DVBSTSHE
  [5] DMVAL ro — DM InputIndicates DM input signal on the HS side of USB port.
  [4] DPVAL ro — DP InputIndicates DP input signal on the HS side of USB port.
  [1] DMINT ro — Indication of Return from DM Interrupt Source
    values as DPUSR1R.DVBSTSH
  [0] DPINT ro — Indication of Return from DP Interrupt Source
    values as DPUSR1R.DVBSTSH
0x16A DPUSRCR 16-bit — Deep Standby USB Suspend/Resume Command Register
  [1] FIXPHYPD — USB Transceiver Control Fix for PLL
    0=Normal mode; 1=Go to/Return from deep software standby mode
  [0] FIXPHY — USB Transceiver Control Fix
    values as FIXPHYPD
0x400 DPUSR0R_FS (reset mask 0xFF4CFFFF) — Deep Software Standby USB Transceiver Control/Pin Monitor Register
  [23] DVBSTS0 ro — USB VBUS InputIndicates the VBUS input signal of the USB.
  [21] DOVCB0 ro — USB OVRCURB InputIndicates the OVRCURB input signal of the USB.
  [20] DOVCA0 ro — USB OVRCURA InputIndicates the OVRCURA input signal of the USB.
  [17] DM0 ro — USB D-InputIndicates the D- input signal of the USB.
  [16] DP0 ro — USB0 D+ InputIndicates the D+ input signal of the USB.
  [4] FIXPHY0 — USB Transceiver Output Fix
    0=The outputs are fixed in normal mode and on return from deep software standby mode; 1=The outputs are fixed on transitions to deep software standby mode
  [3] DRPD0 — D+/D- Pull-Down Resistor Control
    0=Disables DP/DM pull-down resistor; 1=Enables DP/DM pull-down resistor
  [1] RPUE0 — DP Pull-Up Resistor Control
    0=Disables DP pull-up resistor; 1=Enables DP pull-up resistor
  [0] SRPC0 — USB Single End Receiver Control
    0=Input through the DP and DM inputs is disabled; 1=Input through the DP and DM inputs is enabled
0x404 DPUSR1R_FS — Deep Software Standby USB Suspend/Resume Interrupt Register
  [23] DVBINT0 ro — USB VBUS Interrupt Source Recovery
    0=The system has not returned from deep software standby mode; 1=The system has returned from deep software standby mode
  [21] DOVRCRB0 ro — USB OVRCURB Interrupt Source Recovery
    values as DVBINT0
  [20] DOVRCRA0 ro — USB OVRCURA Interrupt Source Recovery
    values as DVBINT0
  [17] DMINT0 ro — USB DM Interrupt Source Recovery
    values as DVBINT0
  [16] DPINT0 ro — USB DP Interrupt Source Recovery
    values as DVBINT0
  [7] DVBSE0 — USB VBUS Interrupt Enable/Clear
    0=Recovery from deep software standby mode is disabled; 1=Recovery from deep software standby mode is enabled
  [5] DOVRCRBE0 — USB OVRCURB Interrupt Enable/Clear
    values as DVBSE0
  [4] DOVRCRAE0 — USB OVRCURA Interrupt Enable/Clear
    values as DVBSE0
  [1] DMINTE0 — USB DM Interrupt Enable/Clear
    values as DVBSE0
  [0] DPINTE0 — USB DP Interrupt Enable/Clear
    values as DVBSE0
